# mutrig_lane_source_mux register map
File version: 26.2.0.0502
Runtime per-lane real, emulator, or mixed round-robin MuTRiG source selector.
Registers are 32-bit, read-only, reset 0x0 unless marked. A register's access mark holds for its fields unless they carry their own. Offsets are from the block's base; lines under a group give offsets from that group; [hi:lo] are bit positions; {n}, {i} and the like mark numbered series; 'fields as' and 'values as' point back to an identical list; <NAME> marks a mode.

## Memory map
0x00000000 mutrig_lane_source_mux size 0x40 — One lane source selector CSR window.

## mutrig_lane_source_mux — One lane source selector CSR window.
Base 0x00000000
0x00 UID reset 0x4D4C534D — IP identifier, default ASCII MLSM.
0x04 META rw reset 0x1A0201F6 — Write page select: 0 VERSION, 1 VERSION_DATE, 2 VERSION_GIT, 3 INSTANCE_ID. Read returns selected page.
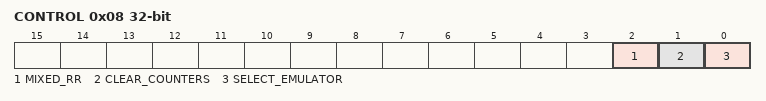
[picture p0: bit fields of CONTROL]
0x08 CONTROL rw — Runtime source control. Bit 0 selects emulator in non-mixed mode. Bit 1 clears counters/FIFOs when written as one. Bit 2 enables mixed round-robin mode.
  [2] MIXED_RR, [1] CLEAR_COUNTERS wo, [0] SELECT_EMULATOR
0x0C STATUS — Live source, sideband, FIFO, and arbitration status.
0x10 REAL_BEATS — Saturating count of real input valid beats.
0x14 EMU_BEATS — Saturating count of emulator input valid beats.
0x18 SELECTED_BEATS — Saturating count of selected output valid beats.
0x1C SWITCH_COUNT — Saturating count of source-mode changes through CONTROL.
0x20 LAST_SELECTED — Last selected source in bit 16, error in bits 15:13, channel in bits 12:9, data in bits 8:0.
0x24 FIFO_STATUS — Mixed-mode FIFO status: real level bits 7:0, emulator level bits 15:8, full/valid/grant bits 20:16.
0x28 REAL_DROPS — Real-input FIFO overflow drops in mixed mode.
0x2C EMU_DROPS — Emulator-input FIFO overflow drops in mixed mode.
0x30 REAL_SELECTED — Selected output beats sourced from real input.
0x34 EMU_SELECTED — Selected output beats sourced from emulator input.
